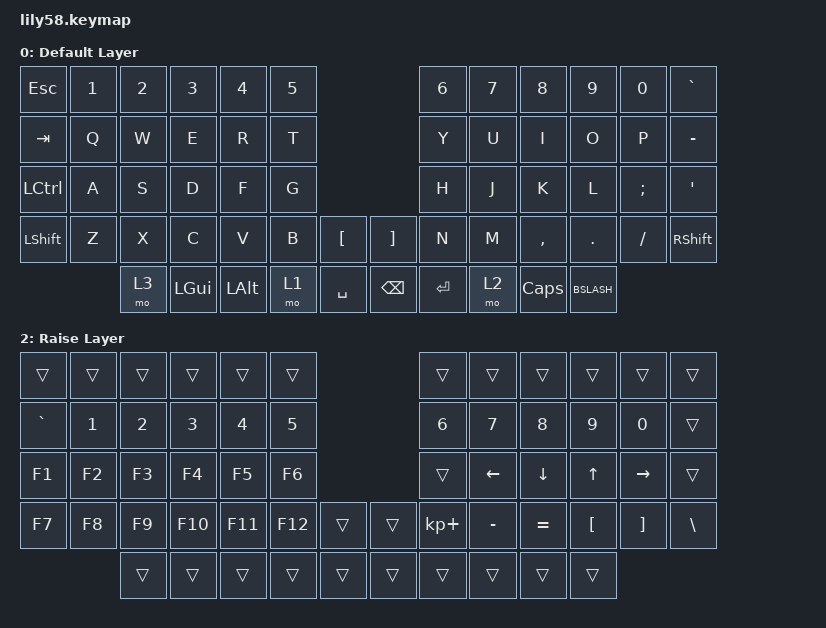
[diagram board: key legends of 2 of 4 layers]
/*
 * Copyright (c) 2020 The ZMK Contributors
 *
 * SPDX-License-Identifier: MIT
 */

#include <behaviors.dtsi>
#include <dt-bindings/zmk/keys.h>
#include <dt-bindings/zmk/bt.h>
#include <dt-bindings/zmk/ext_power.h>

/ {
    behaviors {
    sleep_pc: sleep_macro {
        compatible = "zmk,behavior-macro";
        label = "Sleep PC";
        #binding-cells = <0>;
        bindings = <
            &kp LCTRL
            &kp LALT
            &kp S
        >;
    };
};

    keymap {
        compatible = "zmk,keymap";

        default_layer {
            display-name = "Default Layer";
// ------------------------------------------------------------------------------------------------------------
// |  ESC  |  1  |  2  |  3   |  4   |  5   |                   |  6   |  7    |  8    |  9   |   0   |   =   |
// |  TAB  |  Q  |  W  |  E   |  R   |  T   |                   |  Y   |  U    |  I    |  O   |   P   |   -   |
// |  SHIFT|  A  |  S  |  D   |  F   |  G   |                   |  H   |  J    |  K    |  L   |   ;   |   '   |
// |  CTRL |  Z  |  X  |  C   |  V   |  B   |   "["  |  |  "]"  |  N   |  M    |  ,    |  .   |   /   | SHIFT |
//               |mo 3 | LGUI | LALT | mo 1 |  SPACE |  | BSPC | ENTER | mo 2  | CAPS  |  \   |
            bindings = <
&kp ESC   &kp N1 &kp N2 &kp N3   &kp N4   &kp N5                       &kp N6  &kp N7   &kp N8    &kp N9  &kp N0   &kp GRAVE
&kp TAB   &kp Q  &kp W  &kp E    &kp R    &kp T                        &kp Y   &kp U    &kp I     &kp O   &kp P    &kp MINUS
&kp LCTRL &kp A  &kp S  &kp D    &kp F    &kp G                        &kp H   &kp J    &kp K     &kp L   &kp SEMI &kp SQT
&kp LSHFT &kp Z  &kp X  &kp C    &kp V    &kp B  &kp LBKT     &kp RBKT &kp N   &kp M    &kp COMMA &kp DOT &kp FSLH &kp RSHFT
                 &mo 3  &kp LGUI &kp LALT &mo 1  &kp SPACE    &kp BSPC &kp RET &mo 2    &kp CAPS  &kp BSLASH

            >;

            sensor-bindings = <&inc_dec_kp C_VOL_UP C_VOL_DN>;
        };

        lower_layer {
            display-name = "Lower Layer";
// ------------------------------------------------------------------------------------------------------------
// | BTCLR |     |     |      |      |      |                   |      |       |       |      |       |       |
// |  F1   |  F2 |  F3 |  F4  |  F5  |  F6  |                   |  F7  |  F8   |  F9   |  F10 |  F11  |  F12  |
// |   `   |  !  |  @  |  #   |  $   |  %   |                   |  ^   |  &    |  *    |  (   |   )   |   ~   |
// |       |     |     |      |      |      |    {   |  |   }   |      |  _    |  +    |  {   |   }   |  "|"  |
//                sleep|      |      |      |        |  |       |      |       |       |
            bindings = <
&bt BT_CLR &trans           &trans            &trans            &trans       &trans                       &trans    &trans    &trans    &trans    &trans    &trans
&kp F1     &kp F2           &kp F3            &kp F4            &kp F5       &kp F6                       &kp F7    &kp F8    &kp F9    &kp F10   &kp F11   &kp F12
&kp GRAVE  &kp EXCL         &kp AT            &kp HASH          &kp DOLLAR   &kp PRCNT                    &kp CARET &kp AMPS  &kp ASTRK &kp LPAR  &kp RPAR  &kp TILDE
&trans     &trans           &trans            &trans            &trans       &trans    &kp LPAR &kp RPAR  &kp MINUS &kp PLUS  &kp LBRC  &kp RBRC  &kp PIPE
                            &sleep_pc         &trans            &trans       &trans    &trans   &trans    &trans    &trans    &trans    &trans
            >;

            sensor-bindings = <&inc_dec_kp C_VOL_UP C_VOL_DN>;
        };

        raise_layer {
            display-name = "Raise Layer";
// ------------------------------------------------------------------------------------------------------------
// |       |     |     |      |      |      |                   |      |       |       |      |       |       |
// |   `   |  1  |  2  |  3   |  4   |  5   |                   |  6   |   7   |   8   |  9   |   0   |       |
// |   F1  |  F2 |  F3 |  F4  |  F5  |  F6  |                   |      |   <-  |   v   |  ^   |  ->   |       |
// |   F7  |  F8 |  F9 |  F10 |  F11 |  F12 |        |  |       |  +   |   -   |   =   |  [   |   ]   |   \   |
//                     |      |      |      |        |  |       |      |       |       |
            bindings = <
&trans    &trans &trans &trans  &trans  &trans                       &trans      &trans    &trans    &trans   &trans    &trans
&kp GRAVE &kp N1 &kp N2 &kp N3  &kp N4  &kp N5                       &kp N6      &kp N7    &kp N8    &kp N9   &kp N0    &trans
&kp F1    &kp F2 &kp F3 &kp F4  &kp F5  &kp F6                       &trans      &kp LEFT  &kp DOWN  &kp UP   &kp RIGHT &trans
&kp F7    &kp F8 &kp F9 &kp F10 &kp F11 &kp F12   &trans   &trans    &kp KP_PLUS &kp MINUS &kp EQUAL &kp LBKT &kp RBKT  &kp BSLH
                 &trans &trans  &trans  &trans    &trans   &trans    &trans      &trans    &trans    &trans
            >;

            sensor-bindings = <&inc_dec_kp C_VOL_UP C_VOL_DN>;
        };

        media_layer {
            display-name = "Media Layer";
            bindings = <
                // ------------------------------------------------------------------------------------------------------------
                // |  MUTE | VOL- | VOL+ | PREV | PLAY | NEXT |       |      |      |      |      |      |
                &trans           &trans          &trans        &trans       &trans                &trans
                &trans           &trans          &trans        &trans       &trans                &trans
                &kp MUTE         &kp VOLUME_DOWN &kp VOLUME_UP &kp MEDIA_PREV &kp MEDIA_PLAY_PAUSE &kp MEDIA_NEXT
                &trans           &trans          &trans        &trans       &trans                &trans
                &trans           &trans          &trans        &trans       &trans                &trans
            >;
        };

    };
};
